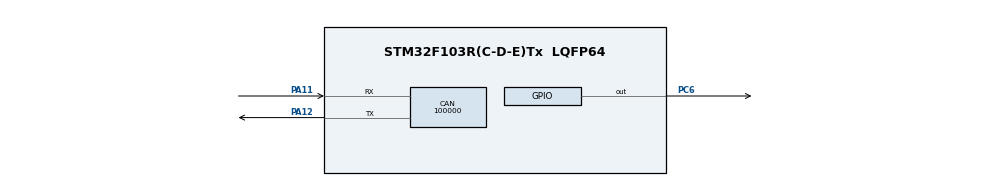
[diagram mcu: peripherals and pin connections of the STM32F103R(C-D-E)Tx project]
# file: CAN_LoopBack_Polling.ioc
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CAN.BS1=CAN_BS1_2TQ
CAN.BS2=CAN_BS2_2TQ
CAN.CalculateBaudRate=100000
CAN.CalculateTimeBit=10000.00
CAN.CalculateTimeQuantum=2000.0
CAN.Mode=CAN_MODE_LOOPBACK
Mcu.Family=STM32F1
Mcu.Name=STM32F103R(C-D-E)Tx
Mcu.Package=LQFP64
NVIC.PriorityGroup=NVIC_PRIORITYGROUP_4
PA11.GPIO_PuPd=GPIO_PULLUP
PA11.Mode=CAN_Activate
PA11.Signal=CAN_RX
PA12.Mode=CAN_Activate
PA12.Signal=CAN_TX
PA13.Mode=Serial_Wire
PA13.Signal=SYS_JTMS-SWDIO
PA14.Mode=Serial_Wire
PA14.Signal=SYS_JTCK-SWCLK
PC6.PinState=GPIO_PIN_RESET
PC6.Signal=GPIO_Output
ProjectManager.HeapSize=0x200
ProjectManager.StackSize=0x400
ProjectManager.TargetToolchain=STM32CubeIDE
RCC.APB1Freq_Value=8000000
RCC.APB2Freq_Value=8000000
board=custom

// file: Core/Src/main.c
/* USER CODE BEGIN Header */
/**
  ******************************************************************************
  * @file           : main.c
  * @brief          : Main program body
  ******************************************************************************
  * @attention
  *
  * <h2><center>&copy; Copyright (c) 2023 STMicroelectronics.
  * All rights reserved.</center></h2>
  *
  * This software component is licensed by ST under BSD 3-Clause license,
  * the "License"; You may not use this file except in compliance with the
  * License. You may obtain a copy of the License at:
  *                        opensource.org/licenses/BSD-3-Clause
  *
  ******************************************************************************
  */
/* USER CODE END Header */
#include "main.h"

CAN_HandleTypeDef hcan;

void SystemClock_Config(void);
static void MX_GPIO_Init(void);
static void MX_CAN_Init(void);

/* USER CODE BEGIN 0 */
CAN_TxHeaderTypeDef TxHeader;
CAN_RxHeaderTypeDef RxHeader;
uint8_t TxData[8];
uint8_t RxData[8];
uint32_t TxMailbox[3];

uint8_t count = 0;
uint8_t num_free_txmailboxes;
//RxData[0] = 0xFF;
/* USER CODE END 0 */

int main(void)
{

  /* MCU Configuration--------------------------------------------------------*/

  /* Reset of all peripherals, Initializes the Flash interface and the Systick. */
  HAL_Init();

  /* USER CODE BEGIN Init */
  uwTickPrio = TICK_INT_PRIORITY;
  /* USER CODE END Init */

  /* Configure the system clock */
  SystemClock_Config();

  /* Initialize all configured peripherals */
  MX_GPIO_Init();
  MX_CAN_Init();
  /* USER CODE BEGIN 2 */
  HAL_CAN_Start(&hcan);

  TxHeader.DLC = 1;
  TxHeader.ExtId = 0;
  TxHeader.IDE = CAN_ID_STD;
  TxHeader.RTR = CAN_RTR_DATA;
  TxHeader.StdId = 0x111;
  TxHeader.TransmitGlobalTime = DISABLE;

  TxData[0] = 0x01;
  TxData[1] = 0x02;
  TxData[2] = 0x03;

  /*
  if (HAL_CAN_AddTxMessage(&hcan, &TxHeader, &TxData[0], &TxMailbox[0]) != HAL_OK)
    {
  	count = 0;
  	Error_Handler();
    }
    if (HAL_CAN_AddTxMessage(&hcan, &TxHeader, &TxData[1], &TxMailbox[1]) != HAL_OK)
    {
  	  count = 1;
  	  Error_Handler();
    }
    if (HAL_CAN_AddTxMessage(&hcan, &TxHeader, &TxData[2], &TxMailbox[2]) != HAL_OK)
    {
  	  count = 2;
  	  Error_Handler();
    }
    */
  HAL_GPIO_WritePin(GPIOC, GPIO_PIN_6, GPIO_PIN_SET);

  /* USER CODE END 2 */

  /* Infinite loop */
  /* USER CODE BEGIN WHILE */
  while (1)
  {
		  HAL_GPIO_WritePin(GPIOC, GPIO_PIN_6, GPIO_PIN_RESET);
		  HAL_Delay(500);
		  HAL_GPIO_WritePin(GPIOC,GPIO_PIN_6,GPIO_PIN_SET);
		  HAL_Delay(500);

	  TxData[0] = 0x00 + count+2;
	  if(count >= 255)
	  	  {
		  	  while(1){
		  		  count--;
		  		  count++;
		  	  }
	  	  }

	  if (HAL_CAN_AddTxMessage(&hcan, &TxHeader, &TxData[0], &TxMailbox[0]) != HAL_OK) //send msg
	      {
	    	count = 69;
	    	Error_Handler();
	      }
	  if(hcan.Instance->TSR & 1)
	  {
		  hcan.Instance->TSR |= 1;
	  }

	  if(HAL_CAN_GetRxFifoFillLevel(&hcan, CAN_RX_FIFO0)) //rec msg
	  	  {
		  	  HAL_CAN_GetRxMessage(&hcan, CAN_RX_FIFO0, &RxHeader, RxData);

	  	  }
	  count++;
	  num_free_txmailboxes = HAL_CAN_GetTxMailboxesFreeLevel(&hcan);
	  HAL_CAN_GetRxFifoFillLevel(&hcan, CAN_RX_FIFO0);
    /* USER CODE END WHILE */

  }
}

void SystemClock_Config(void)
{
  RCC_OscInitTypeDef RCC_OscInitStruct = {0};
  RCC_ClkInitTypeDef RCC_ClkInitStruct = {0};

  /** Initializes the RCC Oscillators according to the specified parameters
  * in the RCC_OscInitTypeDef structure.
  */
  RCC_OscInitStruct.OscillatorType = RCC_OSCILLATORTYPE_HSI;
  RCC_OscInitStruct.HSIState = RCC_HSI_ON;
  RCC_OscInitStruct.HSICalibrationValue = RCC_HSICALIBRATION_DEFAULT;
  RCC_OscInitStruct.PLL.PLLState = RCC_PLL_NONE;
  if (HAL_RCC_OscConfig(&RCC_OscInitStruct) != HAL_OK)
  {
    Error_Handler();
  }
  /** Initializes the CPU, AHB and APB buses clocks
  */
  RCC_ClkInitStruct.ClockType = RCC_CLOCKTYPE_HCLK|RCC_CLOCKTYPE_SYSCLK
                              |RCC_CLOCKTYPE_PCLK1|RCC_CLOCKTYPE_PCLK2;
  RCC_ClkInitStruct.SYSCLKSource = RCC_SYSCLKSOURCE_HSI;
  RCC_ClkInitStruct.AHBCLKDivider = RCC_SYSCLK_DIV1;
  RCC_ClkInitStruct.APB1CLKDivider = RCC_HCLK_DIV1;
  RCC_ClkInitStruct.APB2CLKDivider = RCC_HCLK_DIV1;

  if (HAL_RCC_ClockConfig(&RCC_ClkInitStruct, FLASH_LATENCY_0) != HAL_OK)
  {
    Error_Handler();
  }
}

static void MX_CAN_Init(void)
{

  hcan.Instance = CAN1;
  hcan.Init.Prescaler = 16;
  hcan.Init.Mode = CAN_MODE_LOOPBACK;
  hcan.Init.SyncJumpWidth = CAN_SJW_1TQ;
  hcan.Init.TimeSeg1 = CAN_BS1_2TQ;
  hcan.Init.TimeSeg2 = CAN_BS2_2TQ;
  hcan.Init.TimeTriggeredMode = DISABLE;
  hcan.Init.AutoBusOff = DISABLE;
  hcan.Init.AutoWakeUp = DISABLE;
  hcan.Init.AutoRetransmission = DISABLE;
  hcan.Init.ReceiveFifoLocked = DISABLE;
  hcan.Init.TransmitFifoPriority = DISABLE;
  if (HAL_CAN_Init(&hcan) != HAL_OK)
  {
    Error_Handler();
  }
  /* USER CODE BEGIN CAN_Init 2 */
  CAN_FilterTypeDef canfilterconfig;

    canfilterconfig.FilterActivation = CAN_FILTER_ENABLE; //ENABLE
    canfilterconfig.FilterBank = 10; //0x0000
    canfilterconfig.FilterFIFOAssignment = CAN_RX_FIFO0;
    canfilterconfig.FilterIdHigh = 0x111<<5; //changed from 0x0000
    canfilterconfig.FilterIdLow = 0x0000;
    canfilterconfig.FilterMaskIdHigh = 0x1<<13; //changed from 0
    canfilterconfig.FilterMaskIdLow = 0x0000;
    canfilterconfig.FilterMode = CAN_FILTERMODE_IDMASK;
    canfilterconfig.FilterScale = CAN_FILTERSCALE_32BIT;
    canfilterconfig.SlaveStartFilterBank = 13; // changed from 0

    HAL_CAN_ConfigFilter(&hcan, &canfilterconfig);
  /* USER CODE END CAN_Init 2 */

}

static void MX_GPIO_Init(void)
{
  GPIO_InitTypeDef GPIO_InitStruct = {0};

  /* GPIO Ports Clock Enable */
  __HAL_RCC_GPIOC_CLK_ENABLE();
  __HAL_RCC_GPIOA_CLK_ENABLE();

  /*Configure GPIO pin Output Level */
  HAL_GPIO_WritePin(GPIOC, GPIO_PIN_6, GPIO_PIN_RESET);

  /*Configure GPIO pin : PC6 */
  GPIO_InitStruct.Pin = GPIO_PIN_6;
  GPIO_InitStruct.Mode = GPIO_MODE_OUTPUT_PP;
  GPIO_InitStruct.Pull = GPIO_NOPULL;
  GPIO_InitStruct.Speed = GPIO_SPEED_FREQ_LOW;
  HAL_GPIO_Init(GPIOC, &GPIO_InitStruct);

}

void Error_Handler(void)
{
  __disable_irq();
  while (1)
  {
  }
}

/************************ (C) COPYRIGHT STMicroelectronics *****END OF FILE****/
